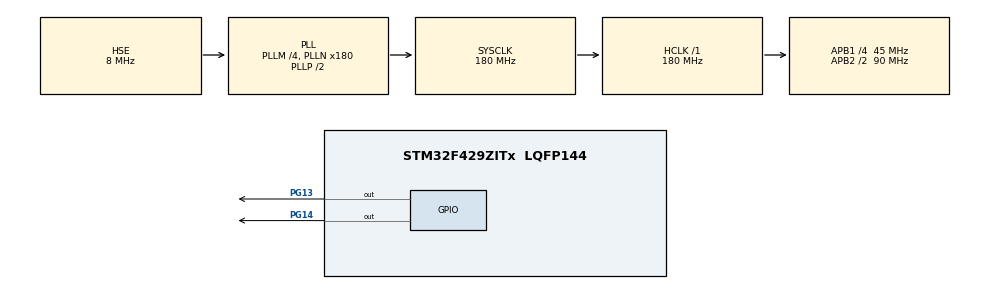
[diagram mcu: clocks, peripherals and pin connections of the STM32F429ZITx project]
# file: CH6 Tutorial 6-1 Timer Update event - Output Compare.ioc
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Mcu.Family=STM32F4
Mcu.Name=STM32F429ZITx
Mcu.Package=LQFP144
NVIC.PriorityGroup=NVIC_PRIORITYGROUP_0
NVIC.TIM1_CC_IRQn=true\:0\:0\:false\:false\:true\:true\:true\:true
NVIC.TIM1_UP_TIM10_IRQn=true\:0\:0\:false\:false\:true\:true\:true\:true
PG13.Signal=GPIO_Output
PG14.Signal=GPIO_Output
PH0/OSC_IN.Mode=HSE-External-Oscillator
PH0/OSC_IN.Signal=RCC_OSC_IN
PH1/OSC_OUT.Mode=HSE-External-Oscillator
PH1/OSC_OUT.Signal=RCC_OSC_OUT
ProjectManager.HeapSize=0x200
ProjectManager.StackSize=0x400
ProjectManager.TargetToolchain=STM32CubeIDE
RCC.48MHZClocksFreq_Value=51428571.428571425
RCC.AHBFreq_Value=180000000
RCC.APB1CLKDivider=RCC_HCLK_DIV4
RCC.APB1Freq_Value=45000000
RCC.APB1TimFreq_Value=90000000
RCC.APB2CLKDivider=RCC_HCLK_DIV2
RCC.APB2Freq_Value=90000000
RCC.APB2TimFreq_Value=180000000
RCC.CortexFreq_Value=180000000
RCC.EnbaleCSS=true
RCC.HCLKFreq_Value=180000000
RCC.HSE_VALUE=8000000
RCC.HSI_VALUE=16000000
RCC.LSE_VALUE=32768
RCC.PLLM=4
RCC.PLLN=180
RCC.PLLQ=7
RCC.PLLSourceVirtual=RCC_PLLSOURCE_HSE
RCC.RCC_MCO1Source=RCC_MCO1SOURCE_PLLCLK
RCC.RCC_MCODiv1=RCC_MCODIV_2
RCC.RCC_MCODiv2=RCC_MCODIV_2
RCC.SYSCLKFreq_VALUE=180000000
RCC.SYSCLKSource=RCC_SYSCLKSOURCE_PLLCLK
RCC.VCOOutputFreq_Value=360000000
TIM1.Channel-Output\ Compare1\ No\ Output=TIM_CHANNEL_1
TIM1.Period=50000-1
TIM1.Prescaler=3600-1
TIM1.Pulse-Output\ Compare1\ No\ Output=25000
TIM1.RepetitionCounter=0
TIM1.TIM_MasterSlaveMode=TIM_MASTERSLAVEMODE_DISABLE
VP_TIM1_VS_ClockSourceINT.Mode=Internal
VP_TIM1_VS_no_output1.Mode=Output Compare1 No Output
board=STM32F429I-DISC1

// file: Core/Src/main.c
/* USER CODE BEGIN Header */
/**
 ******************************************************************************
 * @file           : main.c
 * @brief          : Main program body
 ******************************************************************************
 * @attention
 *
 * Copyright (c) 2023 STMicroelectronics.
 * All rights reserved.
 *
 * This software is licensed under terms that can be found in the LICENSE file
 * in the root directory of this software component.
 * If no LICENSE file comes with this software, it is provided AS-IS.
 *
 ******************************************************************************
 */
	/***************************** Tutorial Tags ******************************
     GPIO Digital outputs
	 Base Timer update event
	 Base Timer Output compare no output
	 Base timer interrupts
	 **************************************************************************/

	/* 6.4.1 Timer Usage C Language: ******************************************
	* Tutorial 6-1: Toggling the red and green LEDs using the TIM1 update and
	* compare interrupts, in     C language

	In this tutorial we are toggling the red and green LEDs on the STM32F4 board. More precisely,
	the green LED, connected to pin PG13 of the board, and red LED, connected to pin
	PG14 of the board, will be toggled at 1 s intervals. There will be a 0.5 s delay
	between the toggling operations in the red and green LEDs.
	***************************************************************************/

/* USER CODE END Header */
#include "main.h"

TIM_HandleTypeDef htim1;

void SystemClock_Config(void);
static void MX_GPIO_Init(void);
static void MX_TIM1_Init(void);

int main(void)
{

  /* MCU Configuration--------------------------------------------------------*/

  /* Reset of all peripherals, Initializes the Flash interface and the Systick. */
  HAL_Init();

  /* Configure the system clock */
  SystemClock_Config();

  /* Initialize all configured peripherals */
  MX_GPIO_Init();
  MX_TIM1_Init();
  /* USER CODE BEGIN 2 */

  // Reset update flag for Timer 1 after being set in timer init function MX_TIM1_Init();"
  if (__HAL_TIM_GET_FLAG(&htim1 , TIM_FLAG_UPDATE) != RESET)
  __HAL_TIM_CLEAR_FLAG(&htim1 , TIM_FLAG_UPDATE);

  HAL_TIM_Base_Start_IT(&htim1);
  HAL_TIM_OC_Start_IT(&htim1 , TIM_CHANNEL_1);

  /* USER CODE END 2 */

  /* Infinite loop */
  while (1)
  {

  }
}

void SystemClock_Config(void)
{
  RCC_OscInitTypeDef RCC_OscInitStruct = {0};
  RCC_ClkInitTypeDef RCC_ClkInitStruct = {0};

  /** Configure the main internal regulator output voltage
  */
  __HAL_RCC_PWR_CLK_ENABLE();
  __HAL_PWR_VOLTAGESCALING_CONFIG(PWR_REGULATOR_VOLTAGE_SCALE1);

  /** Initializes the RCC Oscillators according to the specified parameters
  * in the RCC_OscInitTypeDef structure.
  */
  RCC_OscInitStruct.OscillatorType = RCC_OSCILLATORTYPE_HSE;
  RCC_OscInitStruct.HSEState = RCC_HSE_ON;
  RCC_OscInitStruct.PLL.PLLState = RCC_PLL_ON;
  RCC_OscInitStruct.PLL.PLLSource = RCC_PLLSOURCE_HSE;
  RCC_OscInitStruct.PLL.PLLM = 4;
  RCC_OscInitStruct.PLL.PLLN = 180;
  RCC_OscInitStruct.PLL.PLLP = RCC_PLLP_DIV2;
  RCC_OscInitStruct.PLL.PLLQ = 7;
  if (HAL_RCC_OscConfig(&RCC_OscInitStruct) != HAL_OK)
  {
    Error_Handler();
  }

  /** Activate the Over-Drive mode
  */
  if (HAL_PWREx_EnableOverDrive() != HAL_OK)
  {
    Error_Handler();
  }

  /** Initializes the CPU, AHB and APB buses clocks
  */
  RCC_ClkInitStruct.ClockType = RCC_CLOCKTYPE_HCLK|RCC_CLOCKTYPE_SYSCLK
                              |RCC_CLOCKTYPE_PCLK1|RCC_CLOCKTYPE_PCLK2;
  RCC_ClkInitStruct.SYSCLKSource = RCC_SYSCLKSOURCE_PLLCLK;
  RCC_ClkInitStruct.AHBCLKDivider = RCC_SYSCLK_DIV1;
  RCC_ClkInitStruct.APB1CLKDivider = RCC_HCLK_DIV4;
  RCC_ClkInitStruct.APB2CLKDivider = RCC_HCLK_DIV2;

  if (HAL_RCC_ClockConfig(&RCC_ClkInitStruct, FLASH_LATENCY_5) != HAL_OK)
  {
    Error_Handler();
  }

  /** Enables the Clock Security System
  */
  HAL_RCC_EnableCSS();
}

static void MX_TIM1_Init(void)
{

  TIM_ClockConfigTypeDef sClockSourceConfig = {0};
  TIM_MasterConfigTypeDef sMasterConfig = {0};
  TIM_OC_InitTypeDef sConfigOC = {0};
  TIM_BreakDeadTimeConfigTypeDef sBreakDeadTimeConfig = {0};

  htim1.Instance = TIM1;
  htim1.Init.Prescaler = 3600-1;
  htim1.Init.CounterMode = TIM_COUNTERMODE_UP;
  htim1.Init.Period = 50000-1;
  htim1.Init.ClockDivision = TIM_CLOCKDIVISION_DIV1;
  htim1.Init.RepetitionCounter = 0;
  htim1.Init.AutoReloadPreload = TIM_AUTORELOAD_PRELOAD_DISABLE;
  if (HAL_TIM_Base_Init(&htim1) != HAL_OK)
  {
    Error_Handler();
  }
  sClockSourceConfig.ClockSource = TIM_CLOCKSOURCE_INTERNAL;
  if (HAL_TIM_ConfigClockSource(&htim1, &sClockSourceConfig) != HAL_OK)
  {
    Error_Handler();
  }
  if (HAL_TIM_OC_Init(&htim1) != HAL_OK)
  {
    Error_Handler();
  }
  sMasterConfig.MasterOutputTrigger = TIM_TRGO_RESET;
  sMasterConfig.MasterSlaveMode = TIM_MASTERSLAVEMODE_DISABLE;
  if (HAL_TIMEx_MasterConfigSynchronization(&htim1, &sMasterConfig) != HAL_OK)
  {
    Error_Handler();
  }
  sConfigOC.OCMode = TIM_OCMODE_TIMING;
  sConfigOC.Pulse = 25000;
  sConfigOC.OCPolarity = TIM_OCPOLARITY_HIGH;
  sConfigOC.OCNPolarity = TIM_OCNPOLARITY_HIGH;
  sConfigOC.OCFastMode = TIM_OCFAST_DISABLE;
  sConfigOC.OCIdleState = TIM_OCIDLESTATE_RESET;
  sConfigOC.OCNIdleState = TIM_OCNIDLESTATE_RESET;
  if (HAL_TIM_OC_ConfigChannel(&htim1, &sConfigOC, TIM_CHANNEL_1) != HAL_OK)
  {
    Error_Handler();
  }
  sBreakDeadTimeConfig.OffStateRunMode = TIM_OSSR_DISABLE;
  sBreakDeadTimeConfig.OffStateIDLEMode = TIM_OSSI_DISABLE;
  sBreakDeadTimeConfig.LockLevel = TIM_LOCKLEVEL_OFF;
  sBreakDeadTimeConfig.DeadTime = 0;
  sBreakDeadTimeConfig.BreakState = TIM_BREAK_DISABLE;
  sBreakDeadTimeConfig.BreakPolarity = TIM_BREAKPOLARITY_HIGH;
  sBreakDeadTimeConfig.AutomaticOutput = TIM_AUTOMATICOUTPUT_DISABLE;
  if (HAL_TIMEx_ConfigBreakDeadTime(&htim1, &sBreakDeadTimeConfig) != HAL_OK)
  {
    Error_Handler();
  }

}

static void MX_GPIO_Init(void)
{
  GPIO_InitTypeDef GPIO_InitStruct = {0};

  /* GPIO Ports Clock Enable */
  __HAL_RCC_GPIOH_CLK_ENABLE();
  __HAL_RCC_GPIOG_CLK_ENABLE();

  /*Configure GPIO pin Output Level */
  HAL_GPIO_WritePin(GPIOG, GPIO_PIN_13|GPIO_PIN_14, GPIO_PIN_RESET);

  /*Configure GPIO pins : PG13 PG14 */
  GPIO_InitStruct.Pin = GPIO_PIN_13|GPIO_PIN_14;
  GPIO_InitStruct.Mode = GPIO_MODE_OUTPUT_PP;
  GPIO_InitStruct.Pull = GPIO_NOPULL;
  GPIO_InitStruct.Speed = GPIO_SPEED_FREQ_LOW;
  HAL_GPIO_Init(GPIOG, &GPIO_InitStruct);

}

/* USER CODE BEGIN 4 */
// Callback function to execute following the update event interrupt
void HAL_TIM_PeriodElapsedCallback(TIM_HandleTypeDef *htim){
	HAL_GPIO_TogglePin(GPIOG , GPIO_PIN_13);
}

// Callback function to execute following the capture/compare interrupt
void HAL_TIM_OC_DelayElapsedCallback(TIM_HandleTypeDef *htim){
	HAL_GPIO_TogglePin(GPIOG , GPIO_PIN_14);
}

/* USER CODE END 4 */

void Error_Handler(void)
{
  __disable_irq();
  while (1)
  {
  }
}
